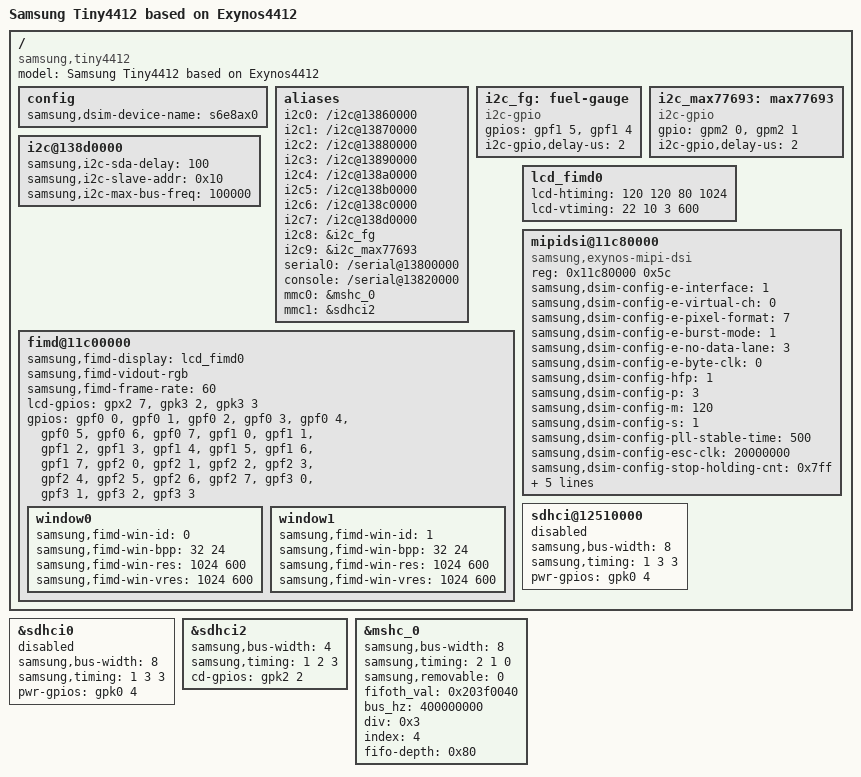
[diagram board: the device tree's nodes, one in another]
/*
 * Samsung's Exynos4412 based Trats2 board device tree source
 *
 * Copyright (c) 2014 Samsung Electronics Co., Ltd.
 *		http://www.samsung.com
 *
 * SPDX-License-Identifier:	GPL-2.0+
 */

/dts-v1/;
#include "exynos4412.dtsi"

/ {
	model = "Samsung Tiny4412 based on Exynos4412";
	compatible = "samsung,tiny4412", "samsung,exynos4412";

	config {
		samsung,dsim-device-name = "s6e8ax0";
	};

	aliases {
		i2c0 = "/i2c@13860000";
		i2c1 = "/i2c@13870000";
		i2c2 = "/i2c@13880000";
		i2c3 = "/i2c@13890000";
		i2c4 = "/i2c@138a0000";
		i2c5 = "/i2c@138b0000";
		i2c6 = "/i2c@138c0000";
		i2c7 = "/i2c@138d0000";
		i2c8 = &i2c_fg;
		i2c9 = &i2c_max77693;
		serial0 = "/serial@13800000";
		console = "/serial@13820000";
		mmc0 = &mshc_0;
		mmc1 = &sdhci2;
	};

	i2c_fg: fuel-gauge {
		compatible = "i2c-gpio";
		gpios = <&gpf1 5 0>,	/* sda */
			<&gpf1 4 0>;	/* scl */
		i2c-gpio,delay-us = <2>;        /* ~100 kHz */
		status = "okay";
	};

	i2c_max77693: max77693 {
		compatible = "i2c-gpio";
		gpio = <&gpm2 0 0>,	/* sda */
		       <&gpm2 1 0>;	/* scl */
		i2c-gpio,delay-us = <2>;        /* ~100 kHz */
		status = "okay";
	};

	i2c@138d0000 {
		samsung,i2c-sda-delay = <100>;
		samsung,i2c-slave-addr = <0x10>;
		samsung,i2c-max-bus-freq = <100000>;
		status = "okay";

	};

fimd@11c00000 {
        //pinctrl-0 = <&lcd_clk &lcd_data24 >;
        pinctrl-names = "default";
        status = "okay";
        samsung,fimd-display = <&lcd_fimd0>;
        samsung,fimd-vidout-rgb;
        samsung,fimd-frame-rate = <60>;

        lcd-gpios = <&gpx2 7 0>,
            <&gpk3 2 0 >,
            <&gpk3 3 0 >;
        gpios=<&gpf0 0 2 >,
            <&gpf0 1 2 >,
            <&gpf0 2 2 >,
            <&gpf0 3 2 >,
            <&gpf0 4 2 >,
            <&gpf0 5 2 >,
            <&gpf0 6 2 >,
            <&gpf0 7 2 >,
            <&gpf1 0 2 >,
            <&gpf1 1 2 >,
            <&gpf1 2 2 >,
            <&gpf1 3 2 >,
            <&gpf1 4 2 >,
            <&gpf1 5 2 >,
            <&gpf1 6 2 >,
            <&gpf1 7 2 >,
            <&gpf2 0 2 >,
            <&gpf2 1 2 >,
            <&gpf2 2 2 >,
            <&gpf2 3 2 >,
            <&gpf2 4 2 >,
            <&gpf2 5 2 >,
            <&gpf2 6 2 >,
            <&gpf2 7 2 >,
            <&gpf3 0 2 >,
            <&gpf3 1 2 >,
            <&gpf3 2 2 >,
            <&gpf3 3 2 >;
        window0 {
            samsung,fimd-win-id = <0>;
            samsung,fimd-win-bpp = <32 24>;
            samsung,fimd-win-res = <1024 600>;
            samsung,fimd-win-vres = <1024 600>;
        };

        window1 {
            samsung,fimd-win-id = <1>;
            samsung,fimd-win-bpp = <32 24>;
            samsung,fimd-win-res = <1024 600>;
            samsung,fimd-win-vres = <1024 600>;
        };
    };

    lcd_fimd0: lcd_fimd0 {
        lcd-htiming = <120 120 80 1024>;
        lcd-vtiming = <22 10 3 600>;
    };

	mipidsi@11c80000 {
		compatible = "samsung,exynos-mipi-dsi";
		reg = <0x11c80000 0x5c>;

		samsung,dsim-config-e-interface = <1>;
		samsung,dsim-config-e-virtual-ch = <0>;
		samsung,dsim-config-e-pixel-format = <7>;
		samsung,dsim-config-e-burst-mode = <1>;
		samsung,dsim-config-e-no-data-lane = <3>;
		samsung,dsim-config-e-byte-clk = <0>;
		samsung,dsim-config-hfp = <1>;

		samsung,dsim-config-p = <3>;
		samsung,dsim-config-m = <120>;
		samsung,dsim-config-s = <1>;

		samsung,dsim-config-pll-stable-time = <500>;
		samsung,dsim-config-esc-clk = <20000000>;
		samsung,dsim-config-stop-holding-cnt = <0x7ff>;
		samsung,dsim-config-bta-timeout = <0xff>;
		samsung,dsim-config-rx-timeout = <0xffff>;

		samsung,dsim-device-id = <0xffffffff>;
		samsung,dsim-device-bus-id = <0>;

		samsung,dsim-device-reverse-panel = <1>;
	};

	sdhci@12510000 {
		samsung,bus-width = <8>;
		samsung,timing = <1 3 3>;
		pwr-gpios = <&gpk0 4 0>;
		status = "disabled";
	};
};

&sdhci0 {
	samsung,bus-width = <8>;
	samsung,timing = <1 3 3>;
	pwr-gpios = <&gpk0 4 0>;
	status = "disabled";
};

&sdhci2 {
	samsung,bus-width = <4>;
	samsung,timing = <1 2 3>;
	cd-gpios = <&gpk2 2 0>;
	status = "okay";
};

&mshc_0 {
	samsung,bus-width = <8>;
	samsung,timing = <2 1 0>;
	samsung,removable = <0>;
	fifoth_val = <0x203f0040>;
	bus_hz = <400000000>;
	div = <0x3>;
	index = <4>;
	fifo-depth = <0x80>;
	status = "okay";
};
